AUTOSAR XML (schema 4-0-3)
standard types defined: Boolean, UInt32
package /AUTOSAR_Platform/DataConstrs
  range DC_Boolean: raw 0..1
package /PATAC/Facility/DataTypes/Implementation
  compu method COMPU_Boolean: 0=FALSE, 1=TRUE
  unit NoUnit: factor-si-to-unit=1, offset-si-to-unit=0
package /PATAC/MSM/ComponentTypes
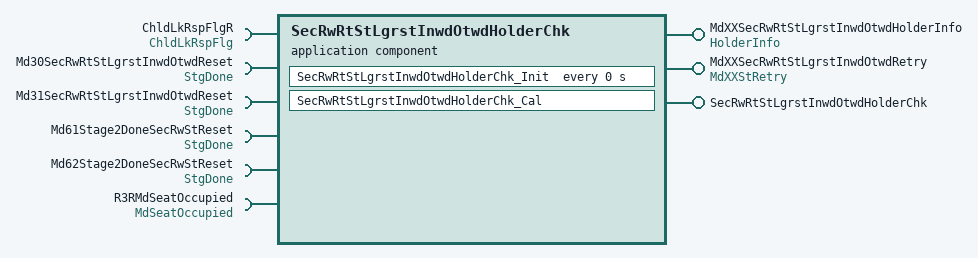
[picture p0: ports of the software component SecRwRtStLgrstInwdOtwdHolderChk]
  application sw component type SecRwRtStLgrstInwdOtwdHolderChk
    provide port MdXXSecRwRtStLgrstInwdOtwdHolderInfo: nonqueued-sender-com-spec{data-element=HolderInfo/Val, init-value=0}, provided-interface=HolderInfo
    provide port MdXXSecRwRtStLgrstInwdOtwdRetry: nonqueued-sender-com-spec{data-element=MdXXStRetry/Val, init-value=0}, provided-interface=MdXXStRetry
    provide port SecRwRtStLgrstInwdOtwdHolderChk: server-com-spec{operation=Cal, queue-length=1}, provided-interface=SecRwRtStLgrstInwdOtwdHolderChk
    6 x require port:
      ChldLkRspFlgR: nonqueued-receiver-com-spec{data-element=ChldLkRspFlg/Val, filter=data-filter-type=ALWAYS, init-value=0}, required-interface=ChldLkRspFlg
      Md30SecRwRtStLgrstInwdOtwdReset: nonqueued-receiver-com-spec{data-element=StgDone/Val, filter=data-filter-type=ALWAYS, init-value=0}, required-interface=StgDone
      Md31SecRwRtStLgrstInwdOtwdReset: nonqueued-receiver-com-spec{data-element=StgDone/Val, filter=data-filter-type=ALWAYS, init-value=0}, required-interface=StgDone
      Md61Stage2DoneSecRwStReset: nonqueued-receiver-com-spec{data-element=StgDone/Val, filter=data-filter-type=ALWAYS, init-value=0}, required-interface=StgDone
      Md62Stage2DoneSecRwStReset: nonqueued-receiver-com-spec{data-element=StgDone/Val, filter=data-filter-type=ALWAYS, init-value=0}, required-interface=StgDone
      R3RMdSeatOccupied: nonqueued-receiver-com-spec{data-element=MdSeatOccupied/Val, filter=data-filter-type=ALWAYS, init-value=0}, required-interface=MdSeatOccupied
    behavior SecRwRtStLgrstInwdOtwdHolderChk_InternalBehavior
      operation invoked event OIT_SecRwRtStLgrstInwdOtwdHolderChk_Cal_SecRwRtStLgrstInwdOtwdHolderChk_Cal: start-on-event=SecRwRtStLgrstInwdOtwdHolderChk_Cal, operation=SecRwRtStLgrstInwdOtwdHolderChk.Cal
      timing event SecRwRtStLgrstInwdOtwdHolderChk_InitEvent: start-on-event=SecRwRtStLgrstInwdOtwdHolderChk_Init, period=0
      runnable SecRwRtStLgrstInwdOtwdHolderChk_Cal
        data-receive-point-by-arguments:
          6 x access:
            REC_ChldLkRspFlgR_Val: accessed-variable=ChldLkRspFlgR.Val
            REC_Md30SecRwRtStLgrstInwdOtwdReset_Val: accessed-variable=Md30SecRwRtStLgrstInwdOtwdReset.Val
            REC_Md31SecRwRtStLgrstInwdOtwdReset_Val: accessed-variable=Md31SecRwRtStLgrstInwdOtwdReset.Val
            REC_Md61Stage2DoneSecRwStReset_Val: accessed-variable=Md61Stage2DoneSecRwStReset.Val
            REC_Md62Stage2DoneSecRwStReset_Val: accessed-variable=Md62Stage2DoneSecRwStReset.Val
            REC_R3RMdSeatOccupied_Val: accessed-variable=R3RMdSeatOccupied.Val
        data-send-points:
          access SEND_MdXXSecRwRtStLgrstInwdOtwdHolderInfo_Val: accessed-variable=MdXXSecRwRtStLgrstInwdOtwdHolderInfo.Val
          access SEND_MdXXSecRwRtStLgrstInwdOtwdRetry_Val: accessed-variable=MdXXSecRwRtStLgrstInwdOtwdRetry.Val
      runnable SecRwRtStLgrstInwdOtwdHolderChk_Init
  swc implementation SecRwRtStLgrstInwdOtwdHolderChk_Implementation: behavior=SecRwRtStLgrstInwdOtwdHolderChk_InternalBehavior
    code-descriptors:
      code Default: artifact-descriptors=autosar-engineering-object={short-label=Default, category=SWSRC}
package /PATAC/MSM/ModeAdjust/PortInterface
  client server interface SecRwRtStLgrstInwdOtwdHolderChk
    operation Cal
  5 x sender receiver interface:
    ChldLkRspFlg: invalidation-policy{data-element=ChldLkRspFlg/Val, handle-invalid=DONT-INVALIDATE}
      data Val: type=Boolean
    HolderInfo: invalidation-policy{data-element=HolderInfo/Val, handle-invalid=DONT-INVALIDATE}
      data Val: type=UInt32
    MdSeatOccupied: invalidation-policy{data-element=MdSeatOccupied/Val, handle-invalid=DONT-INVALIDATE}
      data Val: type=Boolean
    MdXXStRetry: invalidation-policy{data-element=MdXXStRetry/Val, handle-invalid=DONT-INVALIDATE}
      data Val: type=UInt32
    StgDone: invalidation-policy{data-element=StgDone/Val, handle-invalid=DONT-INVALIDATE}
      data Val: type=Boolean
